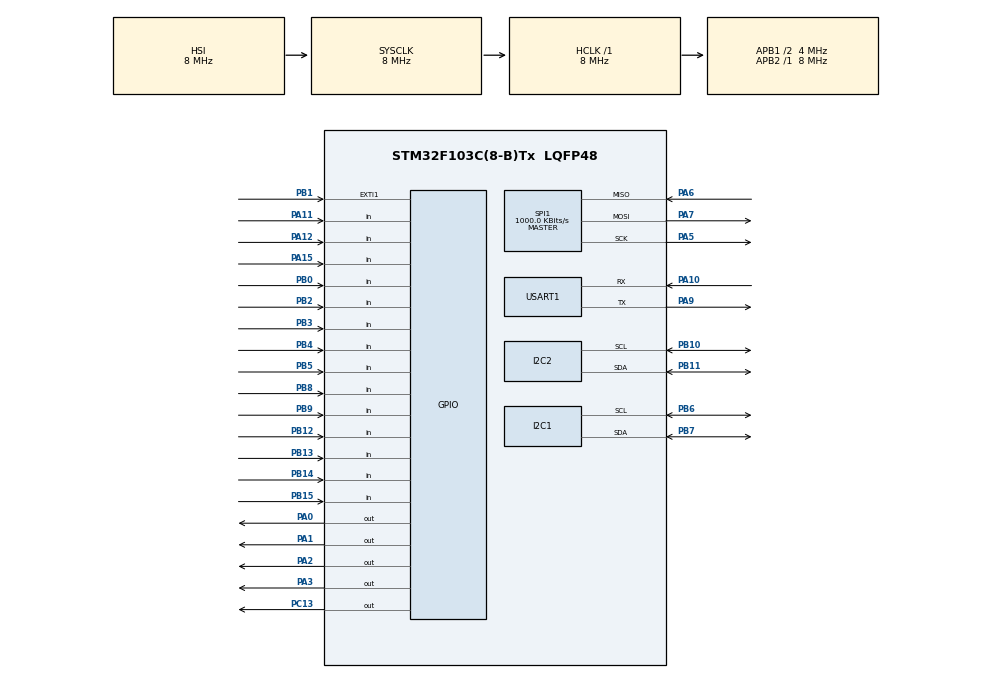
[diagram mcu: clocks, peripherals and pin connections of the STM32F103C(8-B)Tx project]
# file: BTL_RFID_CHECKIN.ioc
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Mcu.Family=STM32F1
Mcu.Name=STM32F103C(8-B)Tx
Mcu.Package=LQFP48
NVIC.EXTI1_IRQn=true\:0\:0\:false\:false\:true\:true\:true\:true
NVIC.PriorityGroup=NVIC_PRIORITYGROUP_4
NVIC.USART1_IRQn=true\:5\:0\:false\:false\:true\:true\:true\:true
PA0-WKUP.GPIO_ModeDefaultOutputPP=GPIO_MODE_OUTPUT_PP
PA0-WKUP.PinState=GPIO_PIN_SET
PA0-WKUP.Signal=GPIO_Output
PA1.PinState=GPIO_PIN_SET
PA1.Signal=GPIO_Output
PA10.Mode=Asynchronous
PA10.Signal=USART1_RX
PA11.GPIO_PuPd=GPIO_NOPULL
PA11.Signal=GPIO_Input
PA12.GPIO_PuPd=GPIO_NOPULL
PA12.Signal=GPIO_Input
PA13.Mode=Serial_Wire
PA13.Signal=SYS_JTMS-SWDIO
PA14.Mode=Serial_Wire
PA14.Signal=SYS_JTCK-SWCLK
PA15.GPIO_PuPd=GPIO_NOPULL
PA15.Signal=GPIO_Input
PA2.PinState=GPIO_PIN_SET
PA2.Signal=GPIO_Output
PA3.PinState=GPIO_PIN_SET
PA3.Signal=GPIO_Output
PA4.Signal=SPI1_NSS
PA5.Mode=Full_Duplex_Master
PA5.Signal=SPI1_SCK
PA6.Mode=Full_Duplex_Master
PA6.Signal=SPI1_MISO
PA7.Mode=Full_Duplex_Master
PA7.Signal=SPI1_MOSI
PA9.Mode=Asynchronous
PA9.Signal=USART1_TX
PB0.GPIO_PuPd=GPIO_NOPULL
PB0.Signal=GPIO_Input
PB1.GPIO_ModeDefaultEXTI=GPIO_MODE_IT_FALLING
PB1.GPIO_PuPd=GPIO_PULLUP
PB1.Signal=GPXTI1
PB10.Mode=SMBus-two-wire-Interface
PB10.Signal=I2C2_SCL
PB11.Mode=SMBus-two-wire-Interface
PB11.Signal=I2C2_SDA
PB12.GPIO_PuPd=GPIO_PULLUP
PB12.Signal=GPIO_Input
PB13.GPIO_PuPd=GPIO_PULLUP
PB13.Signal=GPIO_Input
PB14.GPIO_PuPd=GPIO_NOPULL
PB14.Signal=GPIO_Input
PB15.GPIO_PuPd=GPIO_NOPULL
PB15.Signal=GPIO_Input
PB2.GPIO_PuPd=GPIO_NOPULL
PB2.Signal=GPIO_Input
PB3.GPIO_PuPd=GPIO_PULLUP
PB3.Signal=GPIO_Input
PB4.GPIO_PuPd=GPIO_PULLUP
PB4.Signal=GPIO_Input
PB5.GPIO_PuPd=GPIO_PULLUP
PB5.Signal=GPIO_Input
PB6.Mode=I2C
PB6.Signal=I2C1_SCL
PB7.Mode=I2C
PB7.Signal=I2C1_SDA
PB8.GPIO_PuPd=GPIO_NOPULL
PB8.Signal=GPIO_Input
PB9.GPIO_PuPd=GPIO_PULLUP
PB9.Signal=GPIO_Input
PC13-TAMPER-RTC.Signal=GPIO_Output
PC14-OSC32_IN.Mode=LSE-External-Clock-Source
PC14-OSC32_IN.Signal=RCC_OSC32_IN
PC15-OSC32_OUT.Mode=LSE-External-Clock-Source
PC15-OSC32_OUT.Signal=RCC_OSC32_OUT
PD0-OSC_IN.Mode=HSE-External-Clock-Source
PD0-OSC_IN.Signal=RCC_OSC_IN
PD1-OSC_OUT.Mode=HSE-External-Clock-Source
PD1-OSC_OUT.Signal=RCC_OSC_OUT
ProjectManager.HeapSize=0x200
ProjectManager.StackSize=0x400
ProjectManager.TargetToolchain=STM32CubeIDE
RCC.AHBFreq_Value=8000000
RCC.APB1CLKDivider=RCC_HCLK_DIV2
RCC.APB1Freq_Value=4000000
RCC.APB1TimFreq_Value=8000000
RCC.APB2Freq_Value=8000000
RCC.APB2TimFreq_Value=8000000
RCC.HCLKFreq_Value=8000000
RCC.HSE_Timout=100
RCC.PLLMUL=RCC_PLL_MUL9
RCC.PLLSourceVirtual=RCC_PLLSOURCE_HSE
RCC.SYSCLKFreq_VALUE=8000000
RCC.USBFreq_Value=72000000
SPI1.BaudRatePrescaler=SPI_BAUDRATEPRESCALER_8
SPI1.CalculateBaudRate=1000.0 KBits/s
SPI1.Direction=SPI_DIRECTION_2LINES
SPI1.Mode=SPI_MODE_MASTER
SPI1.VirtualType=VM_MASTER
USART1.VirtualMode=VM_ASYNC
board=custom

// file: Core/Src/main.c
/* USER CODE BEGIN Header */
/**
  ******************************************************************************
  * @file           : main.c
  * @brief          : Main program body
  ******************************************************************************
  * @attention
  *
  * Copyright (c) 2026 STMicroelectronics.
  * All rights reserved.
  *
  * This software is licensed under terms that can be found in the LICENSE file
  * in the root directory of this software component.
  * If no LICENSE file comes with this software, it is provided AS-IS.
  *
  ******************************************************************************
  */
/* USER CODE END Header */
#include "main.h"

/* USER CODE BEGIN Includes */
#include "app_main.h"
void app_main(void);

/* USER CODE END Includes */

I2C_HandleTypeDef hi2c1;

SPI_HandleTypeDef hspi1;

UART_HandleTypeDef huart1;

void SystemClock_Config(void);
static void MX_GPIO_Init(void);
static void MX_USART1_UART_Init(void);
static void MX_SPI1_Init(void);
static void MX_I2C1_Init(void);
static void MX_I2C2_SMBUS_Init(void);

/* USER CODE BEGIN 0 */
/* USER CODE BEGIN 0 */

/* USER CODE END 0 */

int main(void)
{

  /* MCU Configuration--------------------------------------------------------*/

  /* Reset of all peripherals, Initializes the Flash interface and the Systick. */
  HAL_Init();

  /* Configure the system clock */
  SystemClock_Config();

  /* Initialize all configured peripherals */
  MX_GPIO_Init();
  MX_USART1_UART_Init();
  MX_SPI1_Init();
  MX_I2C1_Init();
  MX_I2C2_SMBUS_Init();
  /* USER CODE BEGIN 2 */
  /* USER CODE BEGIN 2 */

  app_main();

  /* USER CODE END 2 */

  /* Infinite loop */
  while (1)
  {

  }
}

void SystemClock_Config(void)
{
  RCC_OscInitTypeDef RCC_OscInitStruct = {0};
  RCC_ClkInitTypeDef RCC_ClkInitStruct = {0};

  /** Initializes the RCC Oscillators according to the specified parameters
  * in the RCC_OscInitTypeDef structure.
  */
  RCC_OscInitStruct.OscillatorType = RCC_OSCILLATORTYPE_HSI;
  RCC_OscInitStruct.HSIState = RCC_HSI_ON;
  RCC_OscInitStruct.HSICalibrationValue = RCC_HSICALIBRATION_DEFAULT;
  RCC_OscInitStruct.PLL.PLLState = RCC_PLL_NONE;
  if (HAL_RCC_OscConfig(&RCC_OscInitStruct) != HAL_OK)
  {
    Error_Handler();
  }

  /** Initializes the CPU, AHB and APB buses clocks
  */
  RCC_ClkInitStruct.ClockType = RCC_CLOCKTYPE_HCLK|RCC_CLOCKTYPE_SYSCLK
                              |RCC_CLOCKTYPE_PCLK1|RCC_CLOCKTYPE_PCLK2;
  RCC_ClkInitStruct.SYSCLKSource = RCC_SYSCLKSOURCE_HSI;
  RCC_ClkInitStruct.AHBCLKDivider = RCC_SYSCLK_DIV1;
  RCC_ClkInitStruct.APB1CLKDivider = RCC_HCLK_DIV2;
  RCC_ClkInitStruct.APB2CLKDivider = RCC_HCLK_DIV1;

  if (HAL_RCC_ClockConfig(&RCC_ClkInitStruct, FLASH_LATENCY_0) != HAL_OK)
  {
    Error_Handler();
  }
}

static void MX_I2C1_Init(void)
{

  hi2c1.Instance = I2C1;
  hi2c1.Init.ClockSpeed = 100000;
  hi2c1.Init.DutyCycle = I2C_DUTYCYCLE_2;
  hi2c1.Init.OwnAddress1 = 0;
  hi2c1.Init.AddressingMode = I2C_ADDRESSINGMODE_7BIT;
  hi2c1.Init.DualAddressMode = I2C_DUALADDRESS_DISABLE;
  hi2c1.Init.OwnAddress2 = 0;
  hi2c1.Init.GeneralCallMode = I2C_GENERALCALL_DISABLE;
  hi2c1.Init.NoStretchMode = I2C_NOSTRETCH_DISABLE;
  if (HAL_I2C_Init(&hi2c1) != HAL_OK)
  {
    Error_Handler();
  }

}

static void MX_I2C2_SMBUS_Init(void)
{

}

static void MX_SPI1_Init(void)
{

  /* SPI1 parameter configuration*/
  hspi1.Instance = SPI1;
  hspi1.Init.Mode = SPI_MODE_MASTER;
  hspi1.Init.Direction = SPI_DIRECTION_2LINES;
  hspi1.Init.DataSize = SPI_DATASIZE_8BIT;
  hspi1.Init.CLKPolarity = SPI_POLARITY_LOW;
  hspi1.Init.CLKPhase = SPI_PHASE_1EDGE;
  hspi1.Init.NSS = SPI_NSS_SOFT;
  hspi1.Init.BaudRatePrescaler = SPI_BAUDRATEPRESCALER_8;
  hspi1.Init.FirstBit = SPI_FIRSTBIT_MSB;
  hspi1.Init.TIMode = SPI_TIMODE_DISABLE;
  hspi1.Init.CRCCalculation = SPI_CRCCALCULATION_DISABLE;
  hspi1.Init.CRCPolynomial = 10;
  if (HAL_SPI_Init(&hspi1) != HAL_OK)
  {
    Error_Handler();
  }

}

static void MX_USART1_UART_Init(void)
{

  huart1.Instance = USART1;
  huart1.Init.BaudRate = 115200;
  huart1.Init.WordLength = UART_WORDLENGTH_8B;
  huart1.Init.StopBits = UART_STOPBITS_1;
  huart1.Init.Parity = UART_PARITY_NONE;
  huart1.Init.Mode = UART_MODE_TX_RX;
  huart1.Init.HwFlowCtl = UART_HWCONTROL_NONE;
  huart1.Init.OverSampling = UART_OVERSAMPLING_16;
  if (HAL_UART_Init(&huart1) != HAL_OK)
  {
    Error_Handler();
  }

}

static void MX_GPIO_Init(void)
{
  GPIO_InitTypeDef GPIO_InitStruct = {0};

  /* GPIO Ports Clock Enable */
  __HAL_RCC_GPIOC_CLK_ENABLE();
  __HAL_RCC_GPIOD_CLK_ENABLE();
  __HAL_RCC_GPIOA_CLK_ENABLE();
  __HAL_RCC_GPIOB_CLK_ENABLE();

  /*Configure GPIO pin Output Level */
  HAL_GPIO_WritePin(GPIOC, GPIO_PIN_13, GPIO_PIN_RESET);

  /*Configure GPIO pin Output Level */
  HAL_GPIO_WritePin(GPIOA, GPIO_PIN_0|GPIO_PIN_1|GPIO_PIN_2|GPIO_PIN_3, GPIO_PIN_SET);

  /*Configure GPIO pin : PC13 */
  GPIO_InitStruct.Pin = GPIO_PIN_13;
  GPIO_InitStruct.Mode = GPIO_MODE_OUTPUT_PP;
  GPIO_InitStruct.Pull = GPIO_NOPULL;
  GPIO_InitStruct.Speed = GPIO_SPEED_FREQ_LOW;
  HAL_GPIO_Init(GPIOC, &GPIO_InitStruct);

  /*Configure GPIO pins : PA0 PA1 PA2 PA3 */
  GPIO_InitStruct.Pin = GPIO_PIN_0|GPIO_PIN_1|GPIO_PIN_2|GPIO_PIN_3;
  GPIO_InitStruct.Mode = GPIO_MODE_OUTPUT_PP;
  GPIO_InitStruct.Pull = GPIO_NOPULL;
  GPIO_InitStruct.Speed = GPIO_SPEED_FREQ_LOW;
  HAL_GPIO_Init(GPIOA, &GPIO_InitStruct);

  /*Configure GPIO pins : PB0 PB2 PB14 PB15
                           PB8 */
  GPIO_InitStruct.Pin = GPIO_PIN_0|GPIO_PIN_2|GPIO_PIN_14|GPIO_PIN_15
                          |GPIO_PIN_8;
  GPIO_InitStruct.Mode = GPIO_MODE_INPUT;
  GPIO_InitStruct.Pull = GPIO_NOPULL;
  HAL_GPIO_Init(GPIOB, &GPIO_InitStruct);

  /*Configure GPIO pin : PB1 */
  GPIO_InitStruct.Pin = GPIO_PIN_1;
  GPIO_InitStruct.Mode = GPIO_MODE_IT_FALLING;
  GPIO_InitStruct.Pull = GPIO_PULLUP;
  HAL_GPIO_Init(GPIOB, &GPIO_InitStruct);

  /*Configure GPIO pins : PB12 PB13 PB3 PB4
                           PB5 PB9 */
  GPIO_InitStruct.Pin = GPIO_PIN_12|GPIO_PIN_13|GPIO_PIN_3|GPIO_PIN_4
                          |GPIO_PIN_5|GPIO_PIN_9;
  GPIO_InitStruct.Mode = GPIO_MODE_INPUT;
  GPIO_InitStruct.Pull = GPIO_PULLUP;
  HAL_GPIO_Init(GPIOB, &GPIO_InitStruct);

  /*Configure GPIO pins : PA11 PA12 PA15 */
  GPIO_InitStruct.Pin = GPIO_PIN_11|GPIO_PIN_12|GPIO_PIN_15;
  GPIO_InitStruct.Mode = GPIO_MODE_INPUT;
  GPIO_InitStruct.Pull = GPIO_NOPULL;
  HAL_GPIO_Init(GPIOA, &GPIO_InitStruct);

  /* EXTI interrupt init*/
  HAL_NVIC_SetPriority(EXTI1_IRQn, 0, 0);
  HAL_NVIC_EnableIRQ(EXTI1_IRQn);

  /* USER CODE BEGIN MX_GPIO_Init_2 */
  HAL_GPIO_WritePin(GPIOB, GPIO_PIN_6|GPIO_PIN_7|GPIO_PIN_10|GPIO_PIN_11, GPIO_PIN_SET);
  GPIO_InitStruct.Pin = GPIO_PIN_6|GPIO_PIN_7|GPIO_PIN_10|GPIO_PIN_11;
  GPIO_InitStruct.Mode = GPIO_MODE_OUTPUT_OD;
  GPIO_InitStruct.Pull = GPIO_NOPULL;
  GPIO_InitStruct.Speed = GPIO_SPEED_FREQ_HIGH;
  HAL_GPIO_Init(GPIOB, &GPIO_InitStruct);

  /* USER CODE END MX_GPIO_Init_2 */
}

void Error_Handler(void)
{
  __disable_irq();
  while (1)
  {
  }
}
